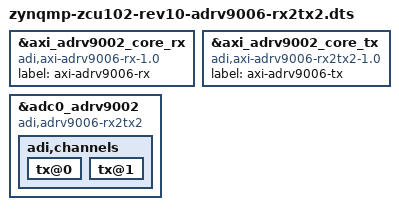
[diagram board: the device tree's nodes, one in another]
// SPDX-License-Identifier: GPL-2.0
/*
 * Analog Devices ADRV9004
 *
 * hdl_project: <adrv9001/zcu102>
 * board_revision: <>
 *
 * Copyright (C) 2025 Analog Devices Inc.
 */

#include "zynqmp-zcu102-rev10-adrv9002-rx2tx2.dts"

&axi_adrv9002_core_rx {
	compatible = "adi,axi-adrv9006-rx-1.0";
	label = "axi-adrv9006-rx";
};

&axi_adrv9002_core_tx {
	compatible = "adi,axi-adrv9006-rx2tx2-1.0";
	label = "axi-adrv9006-tx";
};

&adc0_adrv9002 {
	compatible = "adi,adrv9006-rx2tx2";

	adi,channels {
		tx@0 {
			/delete-property/ adi,dpd;
		};

		tx@1 {
			/delete-property/ adi,dpd;
		};
	};
};
